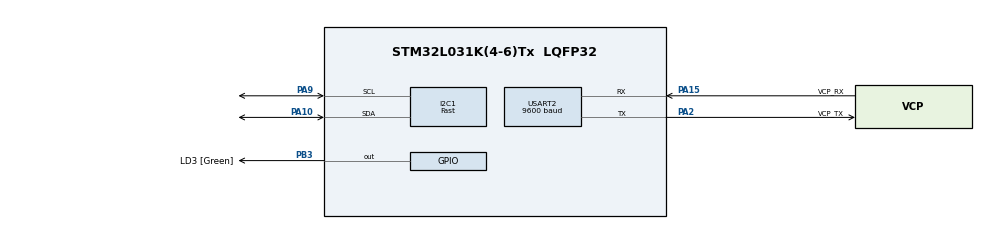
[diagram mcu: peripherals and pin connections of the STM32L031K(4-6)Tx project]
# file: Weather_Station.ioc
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I2C1.I2C_Speed_Mode=I2C_Fast
I2C1.Timing=0x00300F38
Mcu.Family=STM32L0
Mcu.Name=STM32L031K(4-6)Tx
Mcu.Package=LQFP32
NVIC.TIM21_IRQn=true\:0\:0\:false\:false\:true\:true\:true\:true
PA10.Mode=I2C
PA10.Signal=I2C1_SDA
PA13.GPIO_Label=TMS
PA13.Mode=Serial_Wire
PA13.Signal=SYS_SWDIO
PA14.GPIO_Label=TCK
PA14.Mode=Serial_Wire
PA14.Signal=SYS_SWCLK
PA15.GPIO_Label=VCP_RX
PA15.Mode=Asynchronous
PA15.Signal=USART2_RX
PA2.GPIO_Label=VCP_TX
PA2.Mode=Asynchronous
PA2.Signal=USART2_TX
PA9.Mode=I2C
PA9.Signal=I2C1_SCL
PB3.GPIO_Label=LD3 [Green]
PB3.Signal=GPIO_Output
PC14-OSC32_IN.Mode=LSE-External-Oscillator
PC14-OSC32_IN.Signal=RCC_OSC32_IN
PC15-OSC32_OUT.Mode=LSE-External-Oscillator
PC15-OSC32_OUT.Signal=RCC_OSC32_OUT
ProjectManager.HeapSize=0x200
ProjectManager.StackSize=0x400
ProjectManager.TargetToolchain=STM32CubeIDE
RCC.AHBFreq_Value=32000000
RCC.APB1Freq_Value=32000000
RCC.APB1TimFreq_Value=32000000
RCC.APB2Freq_Value=32000000
RCC.APB2TimFreq_Value=32000000
RCC.HCLKFreq_Value=32000000
RCC.HSE_VALUE=8000000
RCC.HSI16_VALUE=16000000
RCC.HSI48_VALUE=48000000
RCC.HSI_VALUE=16000000
RCC.MSI_VALUE=2097000
RCC.PLLMUL=RCC_PLLMUL_4
RCC.SYSCLKFreq_VALUE=32000000
RCC.SYSCLKSource=RCC_SYSCLKSOURCE_PLLCLK
RCC.VCOOutputFreq_Value=64000000
TIM21.Period=1000
TIM21.Prescaler=32000-1
TIM22.Prescaler=32-1
USART2.BaudRate=9600
USART2.VirtualMode-Asynchronous=VM_ASYNC
VP_TIM21_VS_ClockSourceINT.Mode=Internal
VP_TIM22_VS_ClockSourceINT.Mode=Internal
board=NUCLEO-L031K6

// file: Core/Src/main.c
/* USER CODE BEGIN Header */
/**
  ******************************************************************************
  * @file           : main.c
  * @brief          : Main program body
  ******************************************************************************
  * @attention
  *
  * Copyright (c) 2023 STMicroelectronics.
  * All rights reserved.
  *
  * This software is licensed under terms that can be found in the LICENSE file
  * in the root directory of this software component.
  * If no LICENSE file comes with this software, it is provided AS-IS.
  *
  ******************************************************************************
  */
/* USER CODE END Header */
#include "main.h"
#include "i2c.h"
#include "tim.h"
#include "usart.h"
#include "gpio.h"

/* USER CODE BEGIN Includes */
#include "fw_main.h"
/* USER CODE END Includes */

void SystemClock_Config(void);

int main(void)
{

  /* MCU Configuration--------------------------------------------------------*/

  /* Reset of all peripherals, Initializes the Flash interface and the Systick. */
  HAL_Init();

  /* Configure the system clock */
  SystemClock_Config();

  /* Initialize all configured peripherals */
  MX_GPIO_Init();
  MX_USART2_UART_Init();
  MX_TIM21_Init();
  MX_I2C1_Init();
  MX_TIM22_Init();

  /* Infinite loop */
  /* USER CODE BEGIN WHILE */

  // Call Firmware
  fw_main();

  while (1)
  {
    /* USER CODE END WHILE */

  }
}

void SystemClock_Config(void)
{
  LL_FLASH_SetLatency(LL_FLASH_LATENCY_1);
  while(LL_FLASH_GetLatency()!= LL_FLASH_LATENCY_1)
  {
  }
  LL_PWR_SetRegulVoltageScaling(LL_PWR_REGU_VOLTAGE_SCALE1);
  while (LL_PWR_IsActiveFlag_VOS() != 0)
  {
  }
  LL_RCC_HSI_Enable();

   /* Wait till HSI is ready */
  while(LL_RCC_HSI_IsReady() != 1)
  {

  }
  LL_RCC_HSI_SetCalibTrimming(16);
  LL_RCC_PLL_ConfigDomain_SYS(LL_RCC_PLLSOURCE_HSI, LL_RCC_PLL_MUL_4, LL_RCC_PLL_DIV_2);
  LL_RCC_PLL_Enable();

   /* Wait till PLL is ready */
  while(LL_RCC_PLL_IsReady() != 1)
  {

  }
  LL_RCC_SetAHBPrescaler(LL_RCC_SYSCLK_DIV_1);
  LL_RCC_SetAPB1Prescaler(LL_RCC_APB1_DIV_1);
  LL_RCC_SetAPB2Prescaler(LL_RCC_APB2_DIV_1);
  LL_RCC_SetSysClkSource(LL_RCC_SYS_CLKSOURCE_PLL);

   /* Wait till System clock is ready */
  while(LL_RCC_GetSysClkSource() != LL_RCC_SYS_CLKSOURCE_STATUS_PLL)
  {

  }
  LL_SetSystemCoreClock(32000000);

   /* Update the time base */
  if (HAL_InitTick (TICK_INT_PRIORITY) != HAL_OK)
  {
    Error_Handler();
  }
  LL_RCC_SetUSARTClockSource(LL_RCC_USART2_CLKSOURCE_PCLK1);
  LL_RCC_SetI2CClockSource(LL_RCC_I2C1_CLKSOURCE_PCLK1);
}

void Error_Handler(void)
{
  __disable_irq();
  while (1)
  {
  }
}
